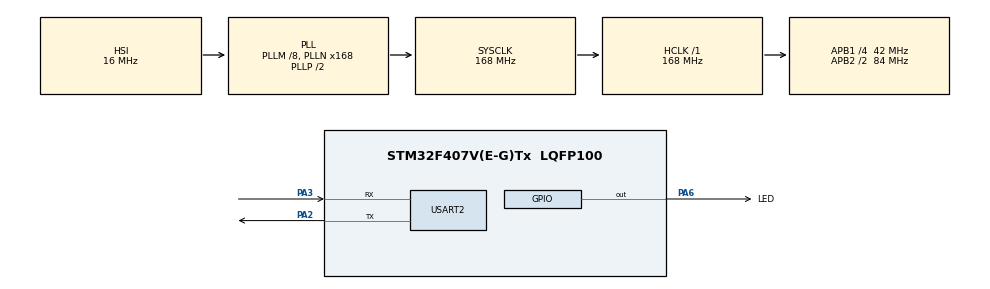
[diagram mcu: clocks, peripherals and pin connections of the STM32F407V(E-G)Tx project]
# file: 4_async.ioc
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Mcu.Family=STM32F4
Mcu.Name=STM32F407V(E-G)Tx
Mcu.Package=LQFP100
NVIC.PriorityGroup=NVIC_PRIORITYGROUP_4
NVIC.USART2_IRQn=true\:0\:0\:false\:false\:true\:true\:true\:true
PA2.Mode=Asynchronous
PA2.Signal=USART2_TX
PA3.Mode=Asynchronous
PA3.Signal=USART2_RX
PA6.GPIO_Label=LED
PA6.Signal=GPIO_Output
ProjectManager.HeapSize=0x200
ProjectManager.StackSize=0x400
ProjectManager.TargetToolchain=STM32CubeIDE
RCC.48MHZClocksFreq_Value=84000000
RCC.AHBFreq_Value=168000000
RCC.APB1CLKDivider=RCC_HCLK_DIV4
RCC.APB1Freq_Value=42000000
RCC.APB1TimFreq_Value=84000000
RCC.APB2CLKDivider=RCC_HCLK_DIV2
RCC.APB2Freq_Value=84000000
RCC.APB2TimFreq_Value=168000000
RCC.CortexFreq_Value=168000000
RCC.HCLKFreq_Value=168000000
RCC.HSE_VALUE=25000000
RCC.HSI_VALUE=16000000
RCC.LSE_VALUE=32768
RCC.PLLM=8
RCC.PLLN=168
RCC.SYSCLKFreq_VALUE=168000000
RCC.SYSCLKSource=RCC_SYSCLKSOURCE_PLLCLK
RCC.VCOOutputFreq_Value=336000000
USART2.OverSampling=UART_OVERSAMPLING_8
USART2.VirtualMode=VM_ASYNC
board=custom

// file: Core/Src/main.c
/* USER CODE BEGIN Header */
/**
 ******************************************************************************
 * @file           : main.c
 * @brief          : Main program body
 ******************************************************************************
 * @attention
 *
 * Copyright (c) 2025 STMicroelectronics.
 * All rights reserved.
 *
 * This software is licensed under terms that can be found in the LICENSE file
 * in the root directory of this software component.
 * If no LICENSE file comes with this software, it is provided AS-IS.
 *
 ******************************************************************************
 */
/* USER CODE END Header */
#include "main.h"

/* USER CODE BEGIN Includes */
#include <string.h>
/* USER CODE END Includes */

UART_HandleTypeDef huart2;

void SystemClock_Config(void);
static void MX_GPIO_Init(void);
static void MX_USART2_UART_Init(void);
/* USER CODE BEGIN PFP */
void HAL_UART_RxCpltCallback(UART_HandleTypeDef *huart);
/* USER CODE END PFP */

/* USER CODE BEGIN 0 */
static uint8_t rx_status;
uint8_t rx_buf[20000] = { 0 };
/* USER CODE END 0 */

int main(void)
{

  /* USER CODE BEGIN 1 */
	char *message = "Hello world\n";
	HAL_UART_Transmit(&huart2, (uint8_t*) message, strlen(message), 100);

  /* USER CODE END 1 */

  /* MCU Configuration--------------------------------------------------------*/

  /* Reset of all peripherals, Initializes the Flash interface and the Systick. */
  HAL_Init();

  /* Configure the system clock */
  SystemClock_Config();

  /* Initialize all configured peripherals */
  MX_GPIO_Init();
  MX_USART2_UART_Init();
  /* USER CODE BEGIN 2 */
	//char *in_buffer = "Hello";
	//uint16_t length = 0;
  /* USER CODE END 2 */

  /* Infinite loop */
  /* USER CODE BEGIN WHILE */
	while (1) {

//		HAL_UART_Transmit(&huart1, (uint8_t*) in_buffer, strlen(in_buffer),
//				100);
//		HAL_UART_Transmit(&huart2, (uint8_t*) in_buffer, strlen(in_buffer),
//				100);
		HAL_StatusTypeDef status =
					HAL_UARTEx_ReceiveToIdle_IT(&huart2, rx_buf, sizeof(rx_buf));
//		if (strncmp("yes", (char*) rx_buf, 3) == 0) {
//			HAL_GPIO_TogglePin(LED_GPIO_Port, LED_Pin);
//			rx_buf[0] = 0;
    /* USER CODE END WHILE */

	}
}

void SystemClock_Config(void)
{
  RCC_OscInitTypeDef RCC_OscInitStruct = {0};
  RCC_ClkInitTypeDef RCC_ClkInitStruct = {0};

  /** Configure the main internal regulator output voltage
  */
  __HAL_RCC_PWR_CLK_ENABLE();
  __HAL_PWR_VOLTAGESCALING_CONFIG(PWR_REGULATOR_VOLTAGE_SCALE1);

  /** Initializes the RCC Oscillators according to the specified parameters
  * in the RCC_OscInitTypeDef structure.
  */
  RCC_OscInitStruct.OscillatorType = RCC_OSCILLATORTYPE_HSI;
  RCC_OscInitStruct.HSIState = RCC_HSI_ON;
  RCC_OscInitStruct.HSICalibrationValue = RCC_HSICALIBRATION_DEFAULT;
  RCC_OscInitStruct.PLL.PLLState = RCC_PLL_ON;
  RCC_OscInitStruct.PLL.PLLSource = RCC_PLLSOURCE_HSI;
  RCC_OscInitStruct.PLL.PLLM = 8;
  RCC_OscInitStruct.PLL.PLLN = 168;
  RCC_OscInitStruct.PLL.PLLP = RCC_PLLP_DIV2;
  RCC_OscInitStruct.PLL.PLLQ = 4;
  if (HAL_RCC_OscConfig(&RCC_OscInitStruct) != HAL_OK)
  {
    Error_Handler();
  }

  /** Initializes the CPU, AHB and APB buses clocks
  */
  RCC_ClkInitStruct.ClockType = RCC_CLOCKTYPE_HCLK|RCC_CLOCKTYPE_SYSCLK
                              |RCC_CLOCKTYPE_PCLK1|RCC_CLOCKTYPE_PCLK2;
  RCC_ClkInitStruct.SYSCLKSource = RCC_SYSCLKSOURCE_PLLCLK;
  RCC_ClkInitStruct.AHBCLKDivider = RCC_SYSCLK_DIV1;
  RCC_ClkInitStruct.APB1CLKDivider = RCC_HCLK_DIV4;
  RCC_ClkInitStruct.APB2CLKDivider = RCC_HCLK_DIV2;

  if (HAL_RCC_ClockConfig(&RCC_ClkInitStruct, FLASH_LATENCY_5) != HAL_OK)
  {
    Error_Handler();
  }
}

static void MX_USART2_UART_Init(void)
{

  huart2.Instance = USART2;
  huart2.Init.BaudRate = 115200;
  huart2.Init.WordLength = UART_WORDLENGTH_8B;
  huart2.Init.StopBits = UART_STOPBITS_1;
  huart2.Init.Parity = UART_PARITY_NONE;
  huart2.Init.Mode = UART_MODE_TX_RX;
  huart2.Init.HwFlowCtl = UART_HWCONTROL_NONE;
  huart2.Init.OverSampling = UART_OVERSAMPLING_8;
  if (HAL_UART_Init(&huart2) != HAL_OK)
  {
    Error_Handler();
  }

}

static void MX_GPIO_Init(void)
{
  GPIO_InitTypeDef GPIO_InitStruct = {0};

  /* GPIO Ports Clock Enable */
  __HAL_RCC_GPIOA_CLK_ENABLE();

  /*Configure GPIO pin Output Level */
  HAL_GPIO_WritePin(LED_GPIO_Port, LED_Pin, GPIO_PIN_RESET);

  /*Configure GPIO pin : LED_Pin */
  GPIO_InitStruct.Pin = LED_Pin;
  GPIO_InitStruct.Mode = GPIO_MODE_OUTPUT_PP;
  GPIO_InitStruct.Pull = GPIO_NOPULL;
  GPIO_InitStruct.Speed = GPIO_SPEED_FREQ_LOW;
  HAL_GPIO_Init(LED_GPIO_Port, &GPIO_InitStruct);

}

/* USER CODE BEGIN 4 */
void HAL_UARTEx_RxEventCallback(UART_HandleTypeDef *huart, uint16_t Size) {
	if (huart == &huart2) {
		rx_status = 1;
		if (strncmp("yes", (char*) rx_buf, 3) == 0) {
			HAL_GPIO_TogglePin(LED_GPIO_Port, LED_Pin);
			rx_buf[0] = 0;
		}
	}
}
/* USER CODE END 4 */

void Error_Handler(void)
{
	__disable_irq();
	while (1) {
	}
}
